# M475 register map
File version: 2.0.2.5
TOSHIBA Cortex-M4 MCU
Registers are 32-bit, read-write, reset 0x0 unless marked. A register's access mark holds for its fields unless they carry their own. Offsets are from the block's base; lines under a group give offsets from that group; [hi:lo] are bit positions; {n}, {i} and the like mark numbered series; 'fields as' and 'values as' point back to an identical list; <NAME> marks a mode.

## Memory map
0x40005000 CANMB0 blocks up to offset 0x1C — CAN Controller (TXCAN) Mailbox RAM
{0x40005000+0x20*n} CANMB{n} blocks up to offset 0x1C (n=1..31)
0x40005400 CAN blocks up to offset 0xBC — CAN Controller (TXCAN)
0x4004C000 DMA blocks up to offset 0x50 — DMA Controller
0x4005F000 DMAIF size 0x4 — DMA Interrupt Flag
0x400C0000 PA blocks up to offset 0x3C — Port A
0x400C0100 PB blocks up to offset 0x3C — Port B
0x400C0200 PC blocks up to offset 0x3C — Port C
0x400C0300 PD blocks up to offset 0x3C — Port D
0x400C0400 PE blocks up to offset 0x3C — Port E
0x400C0500 PF blocks up to offset 0x3C — Port F
0x400C0600 PG blocks up to offset 0x3C — Port G
0x400C0700 PH blocks up to offset 0x3C — Port H
0x400C0800 PJ blocks up to offset 0x3C — Port J
0x400C0900 PK blocks up to offset 0x3C — Port K
0x400C0A00 PL blocks up to offset 0x3C — Port L
0x400C0C00 PN blocks up to offset 0x3C — Port N
0x400C0D00 PP blocks up to offset 0x3C — Port P
0x400C4000 TB0 size 0x30 — 16-bit Timer _ Event Counters (TMRB)
{0x400C4000+0x100*n} TB{n} size 0x30 (n=1..9)
0x400E0000 SBI size 0x18 — Serial Bus Interface(SBI)
0x400E1000 SC0 size 0x34 — Serial Channel (SC)
0x400E1100 SC1 size 0x34
0x400E1200 SC2 size 0x34
0x400E1300 SC3 size 0x34
0x400F1000 OFD size 0x18 — Oscillation Frequency Detector (OFD)
0x400F2000 WD size 0x8 — Watchdog Timer (WD)
0x400F3000 CG blocks up to offset 0x44 — Clock Generator (CG)
0x400F3200 TRMOSC size 0x10 — Internal High-speed Oscillation Adjustment
0x400F3400 NF size 0x8 — Digital Noize FilterClock Control
0x400F4000 VD size 0x4 — Voltage Detection Control Circuit
0x400F6000 PMD0 size 0x68 — Programmable Motor Driver (PMD)
0x400F6100 PMD1 size 0x68
0x400F7000 EN0 size 0x34 — Encoder Input (ENC)
0x400F7100 EN1 size 0x34
0x400F8000 VE0 blocks up to offset 0x210 — Vector Engine (VE)
0x400F8400 VE1 blocks up to offset 0x210
0x400FD000 ADA size 0xE0 — Analog-to-Digital Converter (AD)
0x400FD100 ADB size 0xE0
0x5DFF0000 FC blocks up to offset 0x15C — Flash Control (FC)

## CANMB0 — CAN Controller (TXCAN) Mailbox RAM
Base 0x40005000
Same registers: CANMB{n} {0x40005000+0x20*n} (n=1..31)
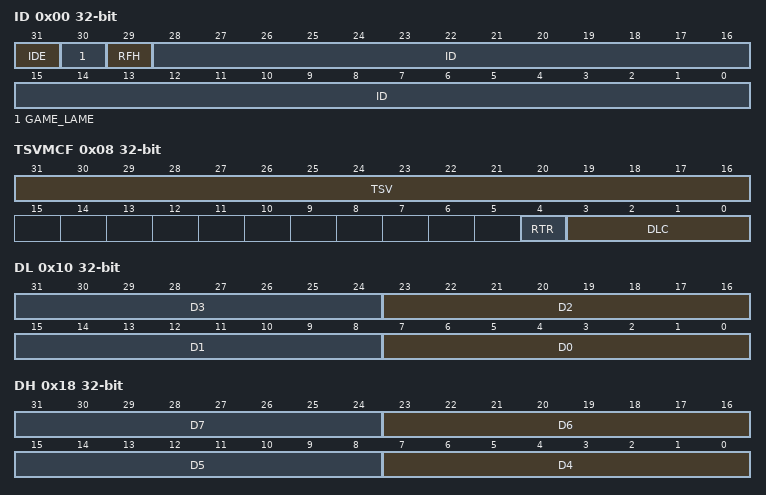
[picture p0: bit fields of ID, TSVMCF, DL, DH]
0x00 ID reset not defined — CAN Mailbox ID
  [31] IDE, [30] GAME_LAME, [29] RFH, [28:0] ID
0x08 TSVMCF reset not defined — CAN Mailbox Time Stamp Value and Message Control Field
  [31:16] TSV, [4] RTR, [3:0] DLC
0x10 DL reset not defined — CAN Mailbox Lower Data Field (D3-D0)
  [8n+7:8n] D{n} (n=0..3)
0x18 DH reset not defined — CAN Mailbox Upper Data Field (D7-D4)
  [8n-25:8n-32] D{n} (n=4..7)

## CAN — CAN Controller (TXCAN)
Base 0x40005400
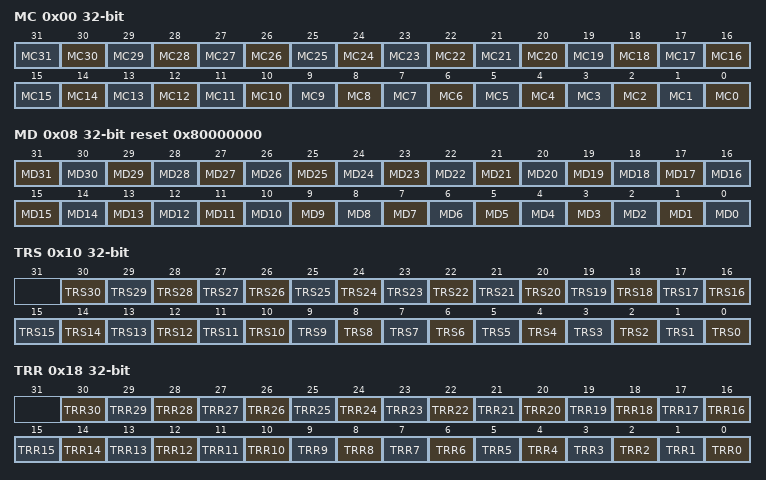
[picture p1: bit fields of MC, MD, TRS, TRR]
0x00 MC — CAN Mailbox Configuration Register
  [n] MC{n} (n=0..31)
0x08 MD reset 0x80000000 — CAN Mailbox Direction Register
  [31] MD31 ro, [n] MD{n} (n=0..30)
0x10 TRS — CAN Transmit Request Set Register
  [n] TRS{n} (n=0..30)
0x18 TRR — CAN Transmit Request Reset Register
  [n] TRR{n} (n=0..30)
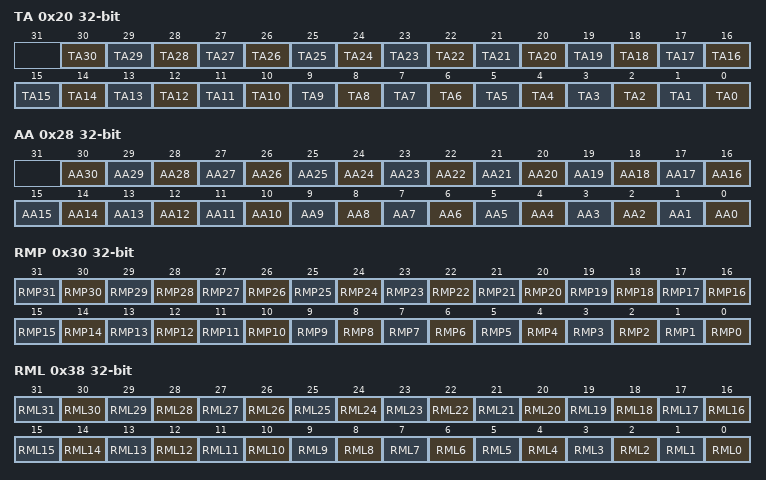
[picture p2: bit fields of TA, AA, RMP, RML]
0x20 TA — CAN Transmission Acknowledge Register
  [n] TA{n} (n=0..30)
0x28 AA — CAN Abort Acknowledge Register
  [n] AA{n} (n=0..30)
0x30 RMP — CAN Receive Message Pending Register
  [n] RMP{n} (n=0..31)
0x38 RML — CAN Receive Message Lost Register
  [n] RML{n} (n=0..31)
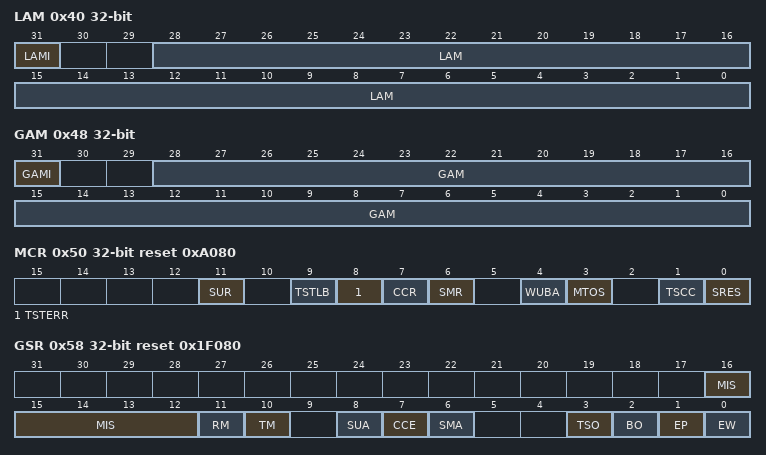
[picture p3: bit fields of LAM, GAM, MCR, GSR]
0x40 LAM — CAN Local Acceptance Mask Register
  [31] LAMI, [28:0] LAM
0x48 GAM — CAN Global Acceptance Mask Register
  [31] GAMI, [28:0] GAM
0x50 MCR reset 0xA080 — CAN Master Control Register
  [11] SUR, [9] TSTLB, [8] TSTERR, [7] CCR, [6] SMR, [4] WUBA, [3] MTOS, [1] TSCC, [0] SRES
0x58 GSR ro reset 0x1F080 — CAN Global Status Register
  [16:12] MIS, [11] RM, [10] TM, [8] SUA, [7] CCE, [6] SMA, [3] TSO, [2] BO, [1] EP, [0] EW
0x60 BCR1 — CAN Bit Configuration Register 1
  [9:0] BRP
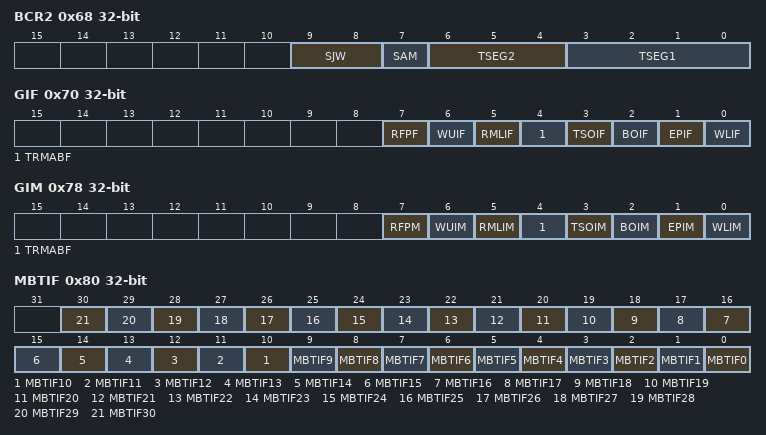
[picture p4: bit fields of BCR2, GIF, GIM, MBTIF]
0x68 BCR2 — CAN Bit Configuration Register 2
  [9:8] SJW, [7] SAM, [6:4] TSEG2, [3:0] TSEG1
0x70 GIF — CAN Global Interrupt Flag Register
  [7] RFPF, [6] WUIF, [5] RMLIF, [4] TRMABF, [3] TSOIF, [2] BOIF, [1] EPIF, [0] WLIF
0x78 GIM — CAN Global Interrupt Mask Register
  [7] RFPM, [6] WUIM, [5] RMLIM, [4] TRMABF, [3] TSOIM, [2] BOIM, [1] EPIM, [0] WLIM
0x80 MBTIF — CAN Mailbox Transmit Interrupt Flag Register
  [n] MBTIF{n} (n=0..30)
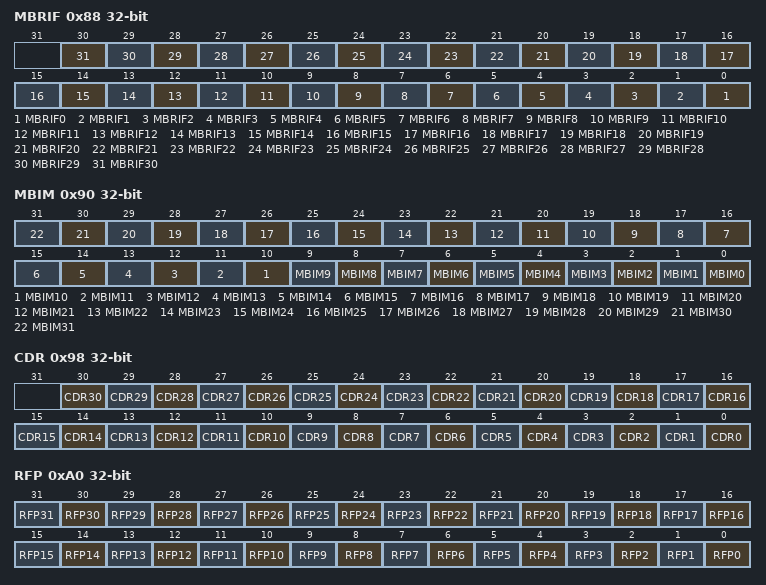
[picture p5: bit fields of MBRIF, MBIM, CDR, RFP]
0x88 MBRIF — CAN Mailbox Receive Interrupt Flag Register
  [n] MBRIF{n} (n=0..30)
0x90 MBIM — CAN Mailbox Interrupt Mask Register
  [n] MBIM{n} (n=0..31)
0x98 CDR — CAN Change Data Request
  [n] CDR{n} (n=0..30)
0xA0 RFP — CAN Remote Frame Pending Register
  [n] RFP{n} (n=0..31)
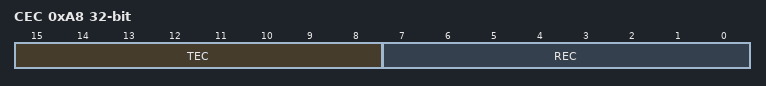
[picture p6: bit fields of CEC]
0xA8 CEC — CAN Error Counter Register
  [15:8] TEC, [7:0] REC
0xB0 TSP — CAN Time Stamp Counter Prescaler Register
  [3:0] TSP
0xB8 TSC — CAN Time Stamp Counter Register
  [15:0] TSC
